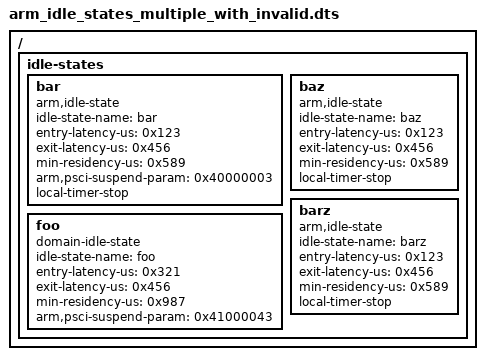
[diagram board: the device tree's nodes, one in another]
// Copyright 2025 The Fuchsia Authors. All rights reserved.
// Use of this source code is governed by a BSD-style license that can be
// found in the LICENSE file.

/dts-v1/;

/ {
    #size-cells = <0x02>;
    #address-cells = <0x02>;
 	idle-states {
		bar {
			compatible = "arm,idle-state";
			idle-state-name = "bar";
			entry-latency-us = <0x123>;
			exit-latency-us = <0x456>;
			min-residency-us = <0x589>;
			arm,psci-suspend-param = <0x40000003>;
			local-timer-stop;
			phandle = <0x1>;
		};

		baz {
			compatible = "arm,idle-state";
			idle-state-name = "baz";
			entry-latency-us = <0x123>;
			exit-latency-us = <0x456>;
			min-residency-us = <0x589>;
			local-timer-stop;
			phandle = <0x2>;
		};

		barz {
			compatible = "arm,idle-state";
			idle-state-name = "barz";
			entry-latency-us = <0x123>;
			exit-latency-us = <0x456>;
			min-residency-us = <0x589>;
			local-timer-stop;
			phandle = <0x3>;
		};

		foo {
			compatible = "domain-idle-state";
			idle-state-name = "foo";
			entry-latency-us = <0x321>;
			exit-latency-us = <0x456>;
			min-residency-us = <0x987>;
			arm,psci-suspend-param = <0x41000043>;
			phandle = <0x4>;
		};
	};
};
